# STM32U5A9 register map
File version: 0.2
CPU: CM33 r0p1, little endian, MPU, FPU, 4 interrupt priority bits
Registers are 32-bit, read-write, reset 0x0 unless marked. A register's access mark holds for its fields unless they carry their own. Offsets are from the block's base; [hi:lo] are bit positions; {n}, {i} and the like mark numbered series.

## RCC (part 2 of 3) — Reset and clock control
Base 0x46020C00
Same registers: SEC_RCC 0x56020C00
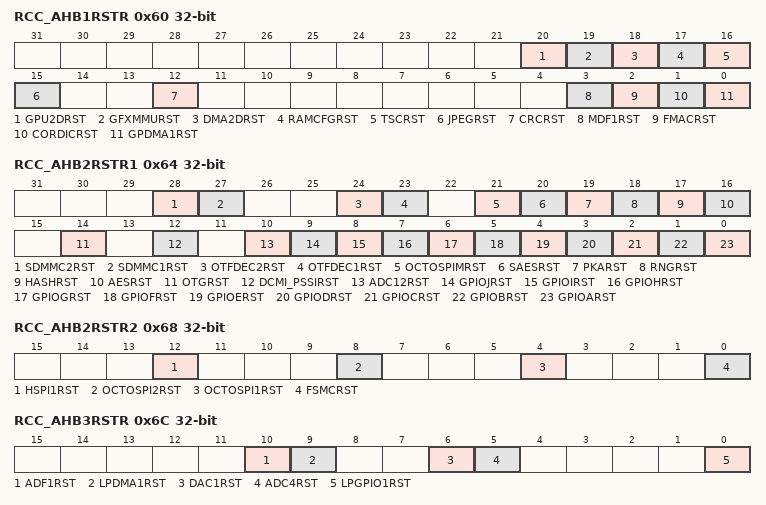
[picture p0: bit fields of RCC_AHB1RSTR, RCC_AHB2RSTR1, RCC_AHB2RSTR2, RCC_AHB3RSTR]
0x60 RCC_AHB1RSTR — RCC AHB1 peripheral reset register
  [20] GPU2DRST — GPU2D reset This bit is set and cleared by software. Note: This bit is only available on some devices in the STM32U5 Series. Refer to the device datasheet for availability of its associated peripheral. If not present, consider this bit as reserved and keep it at reset value.
  [19] GFXMMURST — GFXMMU reset This bit is set and cleared by software. Note: This bit is only available on some devices in the STM32U5 Series. Refer to the device datasheet for availability of its associated peripheral. If not present, consider this bit as reserved and keep it at reset value.
  [18] DMA2DRST — DMA2D reset This bit is set and cleared by software. Note: This bit is only available on some devices in the STM32U5 Series. Refer to the device datasheet for availability of its associated peripheral. If not present, consider this bit as reserved and keep it at reset value.
  [17] RAMCFGRST — RAMCFG reset This bit is set and cleared by software.
  [16] TSCRST — TSC reset This bit is set and cleared by software.
  [15] JPEGRST — JPEG reset This bit is set and cleared by software. Note: This bit is only available on some devices in the STM32U5 Series. Refer to the device datasheet for availability of its associated peripheral. If not present, consider this bit as reserved and keep it at reset value.
  [12] CRCRST — CRC reset This bit is set and cleared by software.
  [3] MDF1RST — MDF1 reset This bit is set and cleared by software.
  [2] FMACRST — FMAC reset This bit is set and cleared by software.
  [1] CORDICRST — CORDIC reset This bit is set and cleared by software.
  [0] GPDMA1RST — GPDMA1 reset This bit is set and cleared by software.
0x64 RCC_AHB2RSTR1 — RCC AHB2 peripheral reset register 1
  [28] SDMMC2RST — SDMMC2 reset This bit is set and cleared by software. Note: This bit is only available on some devices in the STM32U5 Series. Refer to the device datasheet for availability of its associated peripheral. If not present, consider this bit as reserved and keep it at reset value.
  [27] SDMMC1RST — SDMMC1 reset This bit is set and cleared by software.
  [24] OTFDEC2RST — OTFDEC2 reset This bit is set and cleared by software. Note: This bit is only available on some devices in the STM32U5 Series. Refer to the device datasheet for availability of its associated peripheral. If not present, consider this bit as reserved and keep it at reset value.
  [23] OTFDEC1RST — OTFDEC1 reset This bit is set and cleared by software. Note: This bit is only available on some devices in the STM32U5 Series. Refer to the device datasheet for availability of its associated peripheral. If not present, consider this bit as reserved and keep it at reset value.
  [21] OCTOSPIMRST — OCTOSPIM reset This bit is set and cleared by software. Note: This bit is only available on some devices in the STM32U5 Series. Refer to the device datasheet for availability of its associated peripheral. If not present, consider this bit as reserved and keep it at reset value.
  [20] SAESRST — SAES hardware accelerator reset This bit is set and cleared by software. Note: This bit is only available on some devices in the STM32U5 Series. Refer to the device datasheet for availability of its associated peripheral. If not present, consider this bit as reserved and keep it at reset value.
  [19] PKARST — PKA reset This bit is set and cleared by software. Note: This bit is only available on some devices in the STM32U5 Series. Refer to the device datasheet for availability of its associated peripheral. If not present, consider this bit as reserved and keep it at reset value.
  [18] RNGRST — RNG reset This bit is set and cleared by software.
  [17] HASHRST — HASH reset This bit is set and cleared by software.
  [16] AESRST — AES hardware accelerator reset This bit is set and cleared by software. Note: This bit is only available on some devices in the STM32U5 Series. Refer to the device datasheet for availability of its associated peripheral. If not present, consider this bit as reserved and keep it at reset value.
  [14] OTGRST — OTG_FS or OTG_HS reset This bit is set and cleared by software. Note: This bit is only available on some devices in the STM32U5 Series. Refer to the device datasheet for availability of its associated peripheral. If not present, consider this bit as reserved and keep it at reset value.
  [12] DCMI_PSSIRST — DCMI and PSSI reset This bit is set and cleared by software.
  [10] ADC12RST — ADC1 and ADC2 reset This bit is set and cleared by software. Note: This bit impacts ADC1 in STM32U535/545/575/585, and ADC1/ADC2 in�STM32U59x/5Ax/5Fx/5Gx.
  [9] GPIOJRST — I/O port J reset This bit is set and cleared by software. Note: This bit is only available on some devices in the STM32U5 Series. Refer to the device datasheet for availability of its associated peripheral. If not present, consider this bit as reserved and keep it at reset value.
  [8] GPIOIRST — I/O port I reset This bit is set and cleared by software. Note: This bit is only available on some devices in the STM32U5 Series. Refer to the device datasheet for availability of its associated peripheral. If not present, consider this bit as reserved and keep it at reset value.
  [7] GPIOHRST — I/O port H reset This bit is set and cleared by software.
  [6] GPIOGRST — I/O port G reset This bit is set and cleared by software.
  [5] GPIOFRST — I/O port F reset This bit is set and cleared by software. This bit is only available on some devices in the STM32U5 Series. Refer to the device datasheet for availability of its associated peripheral. Note: If not present, consider this bit as reserved and keep it at reset value.
  [4] GPIOERST — I/O port E reset This bit is set and cleared by software.
  [3] GPIODRST — I/O port D reset This bit is set and cleared by software.
  [2] GPIOCRST — I/O port C reset This bit is set and cleared by software.
  [1] GPIOBRST — I/O port B reset This bit is set and cleared by software.
  [0] GPIOARST — I/O port A reset This bit is set and cleared by software.
0x68 RCC_AHB2RSTR2 — RCC AHB2 peripheral reset register 2
  [12] HSPI1RST — HSPI1 reset This bit is set and cleared by software. Note: This bit is only available on some devices in the STM32U5 Series. Refer to the device datasheet for availability of its associated peripheral. If not present, consider this bit as reserved and keep it at reset value.
  [8] OCTOSPI2RST — OCTOSPI2 reset This bit is set and cleared by software. Note: This bit is only available on some devices in the STM32U5 Series. Refer to the device datasheet for availability of its associated peripheral. If not present, consider this bit as reserved and keep it at reset value.
  [4] OCTOSPI1RST — OCTOSPI1 reset This bit is set and cleared by software.
  [0] FSMCRST — Flexible memory controller reset This bit is set and cleared by software. Note: This bit is only available on some devices in the STM32U5 Series. Refer to the device datasheet for availability of its associated peripheral. If not present, consider this bit as reserved and keep it at reset value.
0x6C RCC_AHB3RSTR — RCC AHB3 peripheral reset register
  [10] ADF1RST — ADF1 reset This bit is set and cleared by software.
  [9] LPDMA1RST — LPDMA1 reset This bit is set and cleared by software.
  [6] DAC1RST — DAC1 reset This bit is set and cleared by software.
  [5] ADC4RST — ADC4 reset This bit is set and cleared by software.
  [0] LPGPIO1RST — LPGPIO1 reset This bit is set and cleared by software.
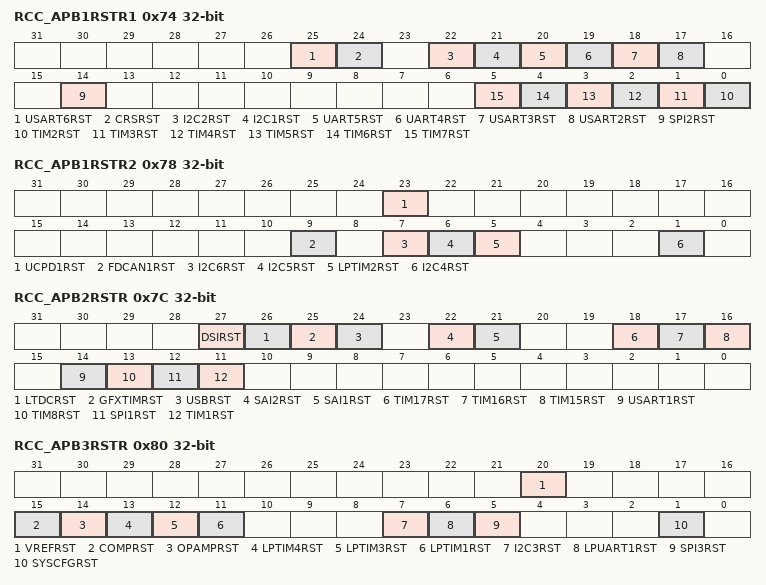
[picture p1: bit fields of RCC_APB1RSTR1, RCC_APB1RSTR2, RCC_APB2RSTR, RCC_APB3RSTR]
0x74 RCC_APB1RSTR1 — RCC APB1 peripheral reset register 1
  [25] USART6RST — USART6 reset This bit is set and cleared by software. Note: This bit is only available on some devices in the STM32U5 Series. Refer to the device datasheet for availability of its associated peripheral. If not present, consider this bit as reserved and keep it at reset value.
  [24] CRSRST — CRS reset This bit is set and cleared by software.
  [22] I2C2RST — I2C2 reset This bit is set and cleared by software.
  [21] I2C1RST — I2C1 reset This bit is set and cleared by software.
  [20] UART5RST — UART5 reset This bit is set and cleared by software.
  [19] UART4RST — UART4 reset This bit is set and cleared by software.
  [18] USART3RST — USART3 reset This bit is set and cleared by software.
  [17] USART2RST — USART2 reset This bit is set and cleared by software. Note: This bit is only available on some devices in the STM32U5 Series.Refer to the device datasheet for availability of its associated peripheral. If not present, consider this bit as reserved and keep it at reset value.
  [14] SPI2RST — SPI2 reset This bit is set and cleared by software.
  [n-2] TIM{n}RST (n=2..7) — TIM{n} reset This bit is set and cleared by software.
0x78 RCC_APB1RSTR2 — RCC APB1 peripheral reset register 2
  [23] UCPD1RST — UCPD1 reset This bit is set and cleared by software. Note: This bit is only available on some devices in the STM32U5 Series. Refer to the device datasheet for availability of its associated peripheral. If not present, consider this bit as reserved and keep it at reset value.
  [9] FDCAN1RST — FDCAN1 reset This bit is set and cleared by software.
  [7] I2C6RST — I2C6 reset This bit is set and cleared by software Note: This bit is only available on some devices in the STM32U5 Series. Refer to the device datasheet for availability of its associated peripheral. If not present, consider this bit as reserved and keep it at reset value.
  [6] I2C5RST — I2C5 reset This bit is set and cleared by software Note: This bit is only available on some devices in the STM32U5 Series. Refer to the device datasheet for availability of its associated peripheral. If not present, consider this bit as reserved and keep it at reset value.
  [5] LPTIM2RST — LPTIM2 reset This bit is set and cleared by software.
  [1] I2C4RST — I2C4 reset This bit is set and cleared by software
0x7C RCC_APB2RSTR — RCC APB2 peripheral reset register
  [27] DSIRST — DSI reset This bit is set and cleared by software. Note: This bit is only available on some devices in the STM32U5 Series. Refer to the device datasheet for availability of its associated peripheral. If not present, consider this bit as reserved and keep it at reset value.
  [26] LTDCRST — LTDC reset This bit is set and cleared by software. Note: This bit is only available on some devices in the STM32U5 Series. Refer to the device datasheet for availability of its associated peripheral. If not present, consider this bit as reserved and keep it at reset value.
  [25] GFXTIMRST — GFXTIM reset This bit is set and cleared by software. Note: .This bit is only available on some devices in the STM32U5 Series. Refer to the device datasheet for availability of its associated peripheral. If not present, consider this bit as reserved and keep it at reset value.
  [24] USBRST — USB reset This bit is set and cleared by software. Note: This bit is only available on some devices in the STM32U5 Series. Refer to the device datasheet for availability of its associated peripheral. If not present, consider this bit as reserved and keep it at reset value.
  [22] SAI2RST — SAI2 reset This bit is set and cleared by software. Note: This bit is only available on some devices in the STM32U5 Series. Refer to the device datasheet for availability of its associated peripheral. If not present, consider this bit as reserved and keep it at reset value.
  [21] SAI1RST — SAI1 reset This bit is set and cleared by software.
  [18] TIM17RST — TIM17 reset This bit is set and cleared by software.
  [17] TIM16RST — TIM16 reset This bit is set and cleared by software.
  [16] TIM15RST — TIM15 reset This bit is set and cleared by software.
  [14] USART1RST — USART1 reset This bit is set and cleared by software.
  [13] TIM8RST — TIM8 reset This bit is set and cleared by software.
  [12] SPI1RST — SPI1 reset This bit is set and cleared by software.
  [11] TIM1RST — TIM1 reset This bit is set and cleared by software.
0x80 RCC_APB3RSTR — RCC APB3 peripheral reset register
  [20] VREFRST — VREFBUF reset This bit is set and cleared by software.
  [15] COMPRST — COMP reset This bit is set and cleared by software.
  [14] OPAMPRST — OPAMP reset This bit is set and cleared by software.
  [13] LPTIM4RST — LPTIM4 reset This bit is set and cleared by software.
  [12] LPTIM3RST — LPTIM3 reset This bit is set and cleared by software.
  [11] LPTIM1RST — LPTIM1 reset This bit is set and cleared by software.
  [7] I2C3RST — I2C3 reset This bit is set and cleared by software.
  [6] LPUART1RST — LPUART1 reset This bit is set and cleared by software.
  [5] SPI3RST — SPI3 reset This bit is set and cleared by software.
  [1] SYSCFGRST — SYSCFG reset This bit is set and cleared by software.
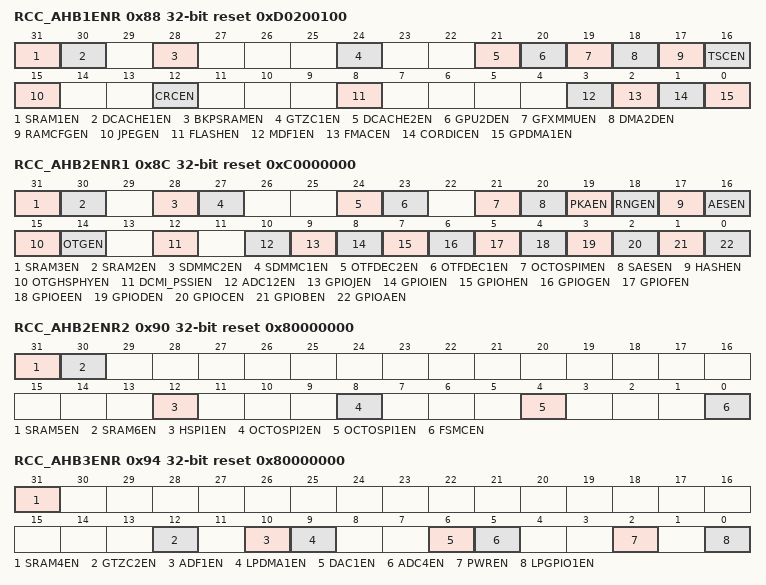
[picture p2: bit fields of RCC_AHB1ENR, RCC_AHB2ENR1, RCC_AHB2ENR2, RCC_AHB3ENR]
0x88 RCC_AHB1ENR reset 0xD0200100 — RCC AHB1 peripheral clock enable register
  [31] SRAM1EN — SRAM1 clock enable This bit is set and reset by software.
  [30] DCACHE1EN — DCACHE1 clock enable This bit is set and reset by software. Note: DCACHE1 clock must be enabled when external memories are accessed through OCTOSPI1, OCTOSPI2, HSPI1 or FSMC, even if the DCACHE1 is bypassed.
  [28] BKPSRAMEN — BKPSRAM clock enable This bit is set and reset by software.
  [24] GTZC1EN — GTZC1 clock enable This bit is set and reset by software.
  [21] DCACHE2EN — DCACHE2 clock enable This bit is set and reset by software. Note: DCACHE2 clock must be enabled to access memories, even if the DCACHE2 is bypassed. Note: This bit is only available on some devices in the STM32U5 Series. Refer to the device datasheet for availability of its associated peripheral. If not present, consider this bit as reserved and keep it at reset value.
  [20] GPU2DEN — GPU2D clock enable This bit is set and cleared by software. Note: This bit is only available on some devices in the STM32U5 Series. Refer to the device datasheet for availability of its associated peripheral. If not present, consider this bit as reserved and keep it at reset value.
  [19] GFXMMUEN — GFXMMU clock enable This bit is set and cleared by software. Note: This bit is only available on some devices in the STM32U5 Series. Refer to the device datasheet for availability of its associated peripheral. If not present, consider this bit as reserved and keep it at reset value.
  [18] DMA2DEN — DMA2D clock enable This bit is set and cleared by software. Note: This bit is only available on some devices in the STM32U5 Series. Refer to the device datasheet for availability of its associated peripheral. If not present, consider this bit as reserved and keep it at reset value.
  [17] RAMCFGEN — RAMCFG clock enable This bit is set and cleared by software.
  [16] TSCEN — Touch sensing controller clock enable This bit is set and cleared by software.
  [15] JPEGEN — JPEG clock enable This bit is set and cleared by software. Note: This bit is only available on some devices in the STM32U5 Series. Refer to the device datasheet for availability of its associated peripheral. If not present, consider this bit as reserved and keep it at reset value.
  [12] CRCEN — CRC clock enable This bit is set and cleared by software.
  [8] FLASHEN — FLASH clock enable This bit is set and cleared by software. This bit can be disabled only when the flash memory is in power-down mode.
  [3] MDF1EN — MDF1 clock enable This bit is set and reset by software.
  [2] FMACEN — FMAC clock enable This bit is set and reset by software.
  [1] CORDICEN — CORDIC clock enable This bit is set and cleared by software.
  [0] GPDMA1EN — GPDMA1 clock enable This bit is set and cleared by software.
0x8C RCC_AHB2ENR1 reset 0xC0000000 — RCC AHB2 peripheral clock enable register 1
  [31] SRAM3EN — SRAM3 clock enable This bit is set and reset by software. Note: This bit is only available on some devices in the STM32U5 Series. Refer to the device datasheet for availability of its associated peripheral. If not present, consider this bit as reserved and keep it at reset value.
  [30] SRAM2EN — SRAM2 clock enable This bit is set and reset by software.
  [28] SDMMC2EN — SDMMC2 clock enable This bit is set and cleared by software. Note: This bit is only available on some devices in the STM32U5 Series. Refer to the device datasheet for availability of its associated peripheral. If not present, consider this bit as reserved and keep it at reset value.
  [27] SDMMC1EN — SDMMC1 clock enable This bit is set and cleared by software.
  [24] OTFDEC2EN — OTFDEC2 clock enable This bit is set and cleared by software. Note: This bit is only available on some devices in the STM32U5 Series. Refer to the device datasheet for availability of its associated peripheral. If not present, consider this bit as reserved and keep it at reset value.
  [23] OTFDEC1EN — OTFDEC1 clock enable This bit is set and cleared by software. Note: This bit is only available on some devices in the STM32U5 Series. Refer to the device datasheet for availability of its associated peripheral. If not present, consider this bit as reserved and keep it at reset value.
  [21] OCTOSPIMEN — OCTOSPIM clock enable This bit is set and cleared by software. Note: This bit is only available on some devices in the STM32U5 Series. Refer to the device datasheet for availability of its associated peripheral. If not present, consider this bit as reserved and keep it at reset value.
  [20] SAESEN — SAES clock enable This bit is set and cleared by software. Note: This bit is only available on some devices in the STM32U5 Series. Refer to the device datasheet for availability of its associated peripheral. If not present, consider this bit as reserved and keep it at reset value.
  [19] PKAEN — PKA clock enable This bit is set and cleared by software. Note: This bit is only available on some devices in the STM32U5 Series. Refer to the device datasheet for availability of its associated peripheral. If not present, consider this bit as reserved and keep it at reset value.
  [18] RNGEN — RNG clock enable This bit is set and cleared by software.
  [17] HASHEN — HASH clock enable This bit is set and cleared by software
  [16] AESEN — AES clock enable This bit is set and cleared by software. Note: This bit is only available on some devices in the STM32U5 Series. Refer to the device datasheet for availability of its associated peripheral. If not present, consider this bit as reserved and keep it at reset value.
  [15] OTGHSPHYEN — OTG_HS PHY clock enable This bit is set and cleared by software. Note: This bit is only available on some devices in the STM32U5 Series. Refer to the device datasheet for availability of its associated peripheral. If not present, consider this bit as reserved and keep it at reset value.
  [14] OTGEN — OTG_FS or OTG_HS clock enable This bit is set and cleared by software. Note: This bit is only available on some devices in the STM32U5 Series. Refer to the device datasheet for availability of its associated peripheral. If not present, consider this bit as reserved and keep it at reset value.
  [12] DCMI_PSSIEN — DCMI and PSSI clock enable This bit is set and cleared by software.
  [10] ADC12EN — ADC1 and ADC2 clock enable This bit is set and cleared by software. Note: This bit impacts ADC1 in STM32U535/545/575/585, and ADC1/ADC2 in�STM32U59x/5Ax/5Fx/5Gx.
  [9] GPIOJEN — I/O port J clock enable This bit is set and cleared by software. Note: This bit is only available on some devices in the STM32U5 Series. Refer to the device datasheet for availability of its associated peripheral. If not present, consider this bit as reserved and keep it at reset value.
  [8] GPIOIEN — I/O port I clock enable This bit is set and cleared by software. Note: This bit is only available on some devices in the STM32U5 Series. Refer to the device datasheet for availability of its associated peripheral. If not present, consider this bit as reserved and keep it at reset value.
  [7] GPIOHEN — I/O port H clock enable This bit is set and cleared by software.
  [6] GPIOGEN — I/O port G clock enable This bit is set and cleared by software.
  [5] GPIOFEN — I/O port F clock enable This bit is set and cleared by software. Note: This bit is only available on some devices in the STM32U5 Series. Refer to the device datasheet for availability of its associated peripheral. If not present, consider this bit as reserved and keep it at reset value.
  [4] GPIOEEN — I/O port E clock enable This bit is set and cleared by software.
  [3] GPIODEN — I/O port D clock enable This bit is set and cleared by software.
  [2] GPIOCEN — I/O port C clock enable This bit is set and cleared by software.
  [1] GPIOBEN — I/O port B clock enable This bit is set and cleared by software.
  [0] GPIOAEN — I/O port A clock enable This bit is set and cleared by software.
0x90 RCC_AHB2ENR2 reset 0x80000000 — RCC AHB2 peripheral clock enable register 2
  [31] SRAM5EN — SRAM5 clock enable This bit is set and reset by software. Note: This bit is only available on some devices in the STM32U5 Series. Refer to the device datasheet for availability of its associated peripheral. If not present, consider this bit as reserved and keep it at reset value.
  [30] SRAM6EN — SRAM6 clock enable This bit is set and reset by software. Note: This bit is only available on some devices in the STM32U5 Series. Refer to the device datasheet for availability of its associated peripheral. If not present, consider this bit as reserved and keep it at reset value.
  [12] HSPI1EN — HSPI1 clock enable This bit is set and cleared by software. Note: This bit is only available on some devices in the STM32U5 Series. Refer to the device datasheet for availability of its associated peripheral. If not present, consider this bit as reserved and keep it at reset value.
  [8] OCTOSPI2EN — OCTOSPI2 clock enable This bit is set and cleared by software. Note: This bit is only available on some devices in the STM32U5 Series. Refer to the device datasheet for availability of its associated peripheral. If not present, consider this bit as reserved and keep it at reset value.
  [4] OCTOSPI1EN — OCTOSPI1 clock enable This bit is set and cleared by software.
  [0] FSMCEN — FSMC clock enable This bit is set and cleared by software. Note: This bit is only available on some devices in the STM32U5 Series. Refer to the device datasheet for availability of its associated peripheral. If not present, consider this bit as reserved and keep it at reset value.
0x94 RCC_AHB3ENR reset 0x80000000 — RCC AHB3 peripheral clock enable register
  [31] SRAM4EN — SRAM4 clock enable This bit is set and reset by software.
  [12] GTZC2EN — GTZC2 clock enable This bit is set and cleared by software.
  [10] ADF1EN — ADF1 clock enable This bit is set and cleared by software.
  [9] LPDMA1EN — LPDMA1 clock enable This bit is set and cleared by software.
  [6] DAC1EN — DAC1 clock enable This bit is set and cleared by software.
  [5] ADC4EN — ADC4 clock enable This bit is set and cleared by software.
  [2] PWREN — PWR clock enable This bit is set and cleared by software.
  [0] LPGPIO1EN — LPGPIO1 enable This bit is set and cleared by software.
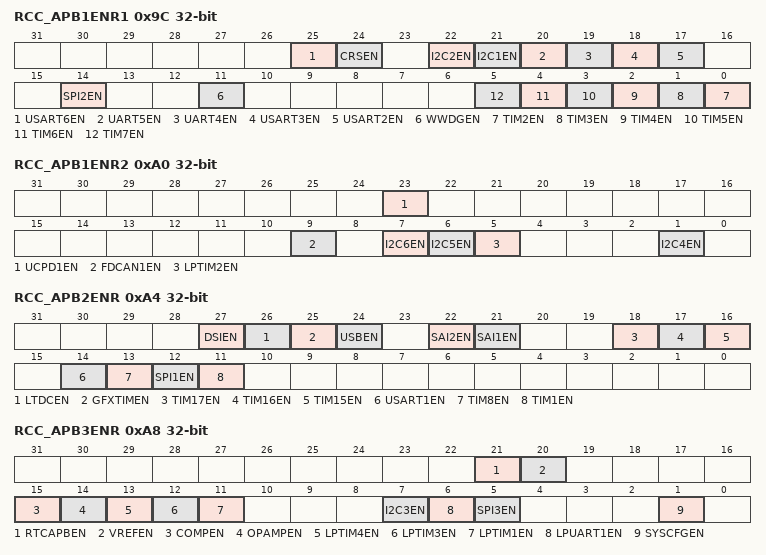
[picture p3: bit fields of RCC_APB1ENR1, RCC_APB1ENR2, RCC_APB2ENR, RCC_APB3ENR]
0x9C RCC_APB1ENR1 — RCC APB1 peripheral clock enable register 1
  [25] USART6EN — USART6 clock enable This bit is set and cleared by software. Note: This bit is only available on some devices in the STM32U5 Series. Refer to the device datasheet for availability of its associated peripheral. If not present, consider this bit as reserved and keep it at reset value.
  [24] CRSEN — CRS clock enable This bit is set and cleared by software.
  [22] I2C2EN — I2C2 clock enable This bit is set and cleared by software.
  [21] I2C1EN — I2C1 clock enable This bit is set and cleared by software.
  [20] UART5EN — UART5 clock enable This bit is set and cleared by software.
  [19] UART4EN — UART4 clock enable This bit is set and cleared by software.
  [18] USART3EN — USART3 clock enable This bit is set and cleared by software.
  [17] USART2EN — USART2 clock enable This bit is set and cleared by software. Note: This bit is only available on some devices in the STM32U5 Series. Refer to the device datasheet for availability of its associated peripheral. If not present, consider this bit as reserved and keep it at reset value.
  [14] SPI2EN — SPI2 clock enable This bit is set and cleared by software.
  [11] WWDGEN — WWDG clock enable This bit is set by software to enable the window watchdog clock. It is reset by hardware system reset. This bit can also be set by hardware if the WWDG_SW option bit is reset.
  [n-2] TIM{n}EN (n=2..7) — TIM{n} clock enable This bit is set and cleared by software.
0xA0 RCC_APB1ENR2 — RCC APB1 peripheral clock enable register 2
  [23] UCPD1EN — UCPD1 clock enable This bit is set and cleared by software. Note: This bit is only available on some devices in the STM32U5 Series. Refer to the device datasheet for availability of its associated peripheral. If not present, consider this bit as reserved and keep it at reset value.
  [9] FDCAN1EN — FDCAN1 clock enable This bit is set and cleared by software.
  [7] I2C6EN — I2C6 clock enable This bit is set and cleared by software. Note: This bit is only available on some devices in the STM32U5 Series. Refer to the device datasheet for availability of its associated peripheral. If not present, consider this bit as reserved and keep it at reset value.
  [6] I2C5EN — I2C5 clock enable This bit is set and cleared by software. Note: This bit is only available on some devices in the STM32U5 Series. Refer to the device datasheet for availability of its associated peripheral. If not present, consider this bit as reserved and keep it at reset value.
  [5] LPTIM2EN — LPTIM2 clock enable This bit is set and cleared by software.
  [1] I2C4EN — I2C4 clock enable This bit is set and cleared by software
0xA4 RCC_APB2ENR — RCC APB2 peripheral clock enable register
  [27] DSIEN — DSI clock enable This bit is set and cleared by software. Note: This bit is only available on some devices in the STM32U5 Series. Refer to the device datasheet for availability of its associated peripheral. If not present, consider this bit as reserved and keep it at reset value.
  [26] LTDCEN — LTDC clock enable This bit is set and cleared by software. Note: This bit is only available on some devices in the STM32U5 Series. Refer to the device datasheet for availability of its associated peripheral. If not present, consider this bit as reserved and keep it at reset value.
  [25] GFXTIMEN — GFXTIM clock enable This bit is set and cleared by software. Note: This bit is only available on some devices in the STM32U5 Series. Refer to the device datasheet for availability of its associated peripheral. If not present, consider this bit as reserved and keep it at reset value.
  [24] USBEN — USB clock enable This bit is set and cleared by software. Note: This bit is only available on some devices in the STM32U5 Series. Refer to the device datasheet for availability of its associated peripheral. If not present, consider this bit as reserved and keep it at reset value.
  [22] SAI2EN — SAI2 clock enable This bit is set and cleared by software. Note: This bit is only available on some devices in the STM32U5 Series. Refer to the device datasheet for availability of its associated peripheral. If not present, consider this bit as reserved and keep it at reset value.
  [21] SAI1EN — SAI1 clock enable This bit is set and cleared by software.
  [18] TIM17EN — TIM17 clock enable This bit is set and cleared by software.
  [17] TIM16EN — TIM16 clock enable This bit is set and cleared by software.
  [16] TIM15EN — TIM15 clock enable This bit is set and cleared by software.
  [14] USART1EN — USART1clock enable This bit is set and cleared by software.
  [13] TIM8EN — TIM8 clock enable This bit is set and cleared by software.
  [12] SPI1EN — SPI1 clock enable This bit is set and cleared by software.
  [11] TIM1EN — TIM1 clock enable This bit is set and cleared by software.
0xA8 RCC_APB3ENR — RCC APB3 peripheral clock enable register
  [21] RTCAPBEN — RTC and TAMP APB clock enable This bit is set and cleared by software.
  [20] VREFEN — VREFBUF clock enable This bit is set and cleared by software.
  [15] COMPEN — COMP clock enable This bit is set and cleared by software.
  [14] OPAMPEN — OPAMP clock enable This bit is set and cleared by software.
  [13] LPTIM4EN — LPTIM4 clock enable This bit is set and cleared by software.
  [12] LPTIM3EN — LPTIM3 clock enable This bit is set and cleared by software.
  [11] LPTIM1EN — LPTIM1 clock enable This bit is set and cleared by software.
  [7] I2C3EN — I2C3 clock enable This bit is set and cleared by software.
  [6] LPUART1EN — LPUART1 clock enable This bit is set and cleared by software.
  [5] SPI3EN — SPI3 clock enable This bit is set and cleared by software.
  [1] SYSCFGEN — SYSCFG clock enable This bit is set and cleared by software.
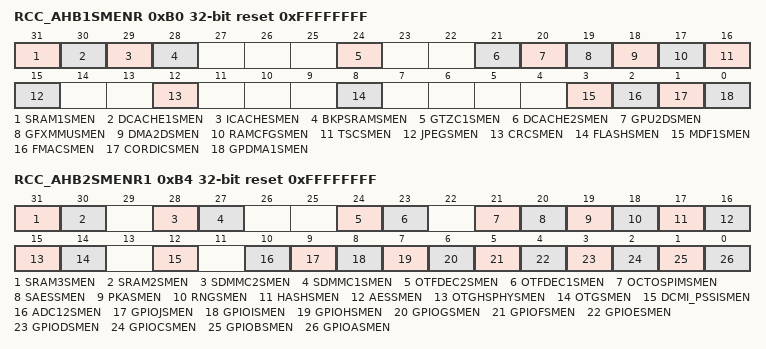
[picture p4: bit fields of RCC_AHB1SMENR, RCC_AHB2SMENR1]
0xB0 RCC_AHB1SMENR reset 0xFFFFFFFF — RCC AHB1 peripheral clock enable in Sleep and Stop modes register
  [31] SRAM1SMEN — SRAM1 clock enable during Sleep and Stop modes This bit is set and cleared by software.
  [30] DCACHE1SMEN — DCACHE1 clock enable during Sleep and Stop modes This bit is set and cleared by software.
  [29] ICACHESMEN — ICACHE clock enable during Sleep and Stop modes This bit is set and cleared by software.
  [28] BKPSRAMSMEN — BKPSRAM clock enable during Sleep and Stop modes This bit is set and cleared by software
  [24] GTZC1SMEN — GTZC1 clock enable during Sleep and Stop modes This bit is set and cleared by software.
  [21] DCACHE2SMEN — DCACHE2 clock enable during Sleep and Stop modes This bit is set and cleared by software. Note: This bit is only available on some devices in the STM32U5 Series. Refer to the device datasheet for availability of its associated peripheral. If not present, consider this bit as reserved and keep it at reset value.
  [20] GPU2DSMEN — GPU2D clock enable during Sleep and Stop modes This bit is set and cleared by software. Note: This bit is only available on some devices in the STM32U5 Series. Refer to the device datasheet for availability of its associated peripheral. If not present, consider this bit as reserved and keep it at reset value.
  [19] GFXMMUSMEN — GFXMMU clock enable during Sleep and Stop modes This bit is set and cleared by software. Note: This bit is only available on some devices in the STM32U5 Series. Refer to the device datasheet for availability of its associated peripheral. If not present, consider this bit as reserved and keep it at reset value.
  [18] DMA2DSMEN — DMA2D clock enable during Sleep and Stop modes This bit is set and cleared by software. Note: This bit is only available on some devices in the STM32U5 Series. Refer to the device datasheet for availability of its associated peripheral. If not present, consider this bit as reserved and keep it at reset value.
  [17] RAMCFGSMEN — RAMCFG clock enable during Sleep and Stop modes This bit is set and cleared by software.
  [16] TSCSMEN — TSC clocks enable during Sleep and Stop modes This bit is set and cleared by software.
  [15] JPEGSMEN — JPEG clocks enable during Sleep and Stop modes This bit is set and cleared by software. Note: This bit is only available on some devices in the STM32U5 Series. Refer to the device datasheet for availability of its associated peripheral. If not present, consider this bit as reserved and keep it at reset value.
  [12] CRCSMEN — CRC clocks enable during Sleep and Stop modes This bit is set and cleared by software.
  [8] FLASHSMEN — FLASH clocks enable during Sleep and Stop modes This bit is set and cleared by software.
  [3] MDF1SMEN — MDF1 clocks enable during Sleep and Stop modes. This bit is set and cleared by software. Note: This bit must be set to allow the peripheral to wake up from Stop modes.
  [2] FMACSMEN — FMAC clocks enable during Sleep and Stop modes. This bit is set and cleared by software.
  [1] CORDICSMEN — CORDIC clocks enable during Sleep and Stop modes This bit is set and cleared by software during Sleep mode.
  [0] GPDMA1SMEN — GPDMA1 clocks enable during Sleep and Stop modes This bit is set and cleared by software. Note: This bit must be set to allow the peripheral to wake up from Stop modes.
0xB4 RCC_AHB2SMENR1 reset 0xFFFFFFFF — RCC AHB2 peripheral clock enable in Sleep and Stop modes register 1
  [31] SRAM3SMEN — SRAM3 clock enable during Sleep and Stop modes This bit is set and cleared by software. Note: This bit is only available on some devices in the STM32U5 Series. Refer to the device datasheet for availability of its associated peripheral. If not present, consider this bit as reserved and keep it at reset value.
  [30] SRAM2SMEN — SRAM2 clock enable during Sleep and Stop modes This bit is set and cleared by software.
  [28] SDMMC2SMEN — SDMMC2 clock enable during Sleep and Stop modes This bit is set and cleared by software. Note: This bit is only available on some devices in the STM32U5 Series. Refer to the device datasheet for availability of its associated peripheral. If not present, consider this bit as reserved and keep it at reset value.
  [27] SDMMC1SMEN — SDMMC1 clock enable during Sleep and Stop modes This bit is set and cleared by software.
  [24] OTFDEC2SMEN — OTFDEC2 clock enable during Sleep and Stop modes This bit is set and cleared by software. Note: This bit is only available on some devices in the STM32U5 Series. Refer to the device datasheet for availability of its associated peripheral. If not present, consider this bit as reserved and keep it at reset value.
  [23] OTFDEC1SMEN — OTFDEC1 clock enable during Sleep and Stop modes This bit is set and cleared by software. Note: This bit is only available on some devices in the STM32U5 Series. Refer to the device datasheet for availability of its associated peripheral. If not present, consider this bit as reserved and keep it at reset value.
  [21] OCTOSPIMSMEN — OCTOSPIM clock enable during Sleep and Stop modes This bit is set and cleared by software. Note: This bit is only available on some devices in the STM32U5 Series. Refer to the device datasheet for availability of its associated peripheral. If not present, consider this bit as reserved and keep it at reset value.
  [20] SAESSMEN — SAES accelerator clock enable during Sleep and Stop modes This bit is set and cleared by software. Note: This bit is only available on some devices in the STM32U5 Series. Refer to the device datasheet for availability of its associated peripheral. If not present, consider this bit as reserved and keep it at reset value.
  [19] PKASMEN — PKA clock enable during Sleep and Stop modes This bit is set and cleared by software. Note: This bit is only available on some devices in the STM32U5 Series. Refer to the device datasheet for availability of its associated peripheral. If not present, consider this bit as reserved and keep it at reset value.
  [18] RNGSMEN — RNG clock enable during Sleep and Stop modes This bit is set and cleared by software.
  [17] HASHSMEN — HASH clock enable during Sleep and Stop modes This bit is set and cleared by software
  [16] AESSMEN — AES clock enable during Sleep and Stop modes This bit is set and cleared by software Note: This bit is only available on some devices in the STM32U5 Series. Refer to the device datasheet for availability of its associated peripheral. If not present, consider this bit as reserved and keep it at reset value.
  [15] OTGHSPHYSMEN — OTG_HS PHY clock enable during Sleep and Stop modes This bit is set and cleared by software Note: This bit is only available on some devices in the STM32U5 Series. Refer to the device datasheet for availability of its associated peripheral. If not present, consider this bit as reserved and keep it at reset value.
  [14] OTGSMEN — OTG_FS and OTG_HS clocks enable during Sleep and Stop modes This bit is set and cleared by software. Note: This bit is only available on some devices in the STM32U5 Series. Refer to the device datasheet for availability of its associated peripheral. If not present, consider this bit as reserved and keep it at reset value.
  [12] DCMI_PSSISMEN — DCMI and PSSI clock enable during Sleep and Stop modes This bit is set and cleared by software.
  [10] ADC12SMEN — ADC1 and ADC2 clock enable during Sleep and Stop modes This bit is set and cleared by software. Note: This bit impacts ADC1 in STM32U535/545/575/585 and ADC1/ADC2 in�STM32U59x/5Ax/5Fx/5Gx.
  [9] GPIOJSMEN — I/O port J clock enable during Sleep and Stop modes This bit is set and cleared by software. Note: This bit is only available on some devices in the STM32U5 Series. Refer to the device datasheet for availability of its associated peripheral. If not present, consider this bit as reserved and keep it at reset value.
  [8] GPIOISMEN — I/O port I clocks enable during Sleep and Stop modes This bit is set and cleared by software. Note: This bit is only available on some devices in the STM32U5 Series. Refer to the device datasheet for availability of its associated peripheral. If not present, consider this bit as reserved and keep it at reset value.
  [7] GPIOHSMEN — I/O port H clocks enable during Sleep and Stop modes This bit is set and cleared by software.
  [6] GPIOGSMEN — I/O port G clocks enable during Sleep and Stop modes This bit is set and cleared by software.
  [5] GPIOFSMEN — I/O port F clocks enable during Sleep and Stop modes This bit is set and cleared by software. Note: This bit is only available on some devices in the STM32U5 Series. Refer to the device datasheet for availability of its associated peripheral. If not present, consider this bit as reserved and keep it at reset value.
  [4] GPIOESMEN — I/O port E clocks enable during Sleep and Stop modes This bit is set and cleared by software.
  [3] GPIODSMEN — I/O port D clocks enable during Sleep and Stop modes This bit is set and cleared by software.
  [2] GPIOCSMEN — I/O port C clocks enable during Sleep and Stop modes This bit is set and cleared by software.
  [1] GPIOBSMEN — I/O port B clocks enable during Sleep and Stop modes This bit is set and cleared by software.
  [0] GPIOASMEN — I/O port A clocks enable during Sleep and Stop modes This bit is set and cleared by software.
